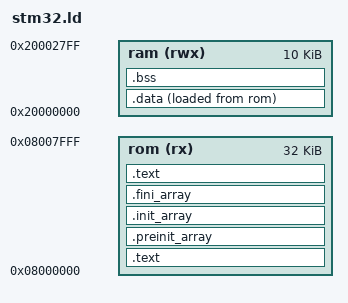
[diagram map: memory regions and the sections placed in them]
/*
 * This file is part of the libopencm3 project.
 *
 * Copyright (C) 2012 Karl Palsson <karlp@tweak.net.au>
 *
 * This library is free software: you can redistribute it and/or modify
 * it under the terms of the GNU Lesser General Public License as published by
 * the Free Software Foundation, either version 3 of the License, or
 * (at your option) any later version.
 *
 * This library is distributed in the hope that it will be useful,
 * but WITHOUT ANY WARRANTY; without even the implied warranty of
 * MERCHANTABILITY or FITNESS FOR A PARTICULAR PURPOSE.  See the
 * GNU Lesser General Public License for more details.
 *
 * You should have received a copy of the GNU Lesser General Public License
 * along with this library.  If not, see <http://www.gnu.org/licenses/>.
 */

/* Linker script for STM32F100x6, 32K flash, 4K RAM. */

/* Define memory regions. */
MEMORY
{
	rom (rx) : ORIGIN = 0x08000000, LENGTH = 32K
	ram (rwx) : ORIGIN = 0x20000000, LENGTH = 10K
}

/* Include the common ld script. */

/*
 * This file is part of the libopencm3 project.
 *
 * Copyright (C) 2009 Uwe Hermann <uwe@hermann-uwe.de>
 *
 * This library is free software: you can redistribute it and/or modify
 * it under the terms of the GNU Lesser General Public License as published by
 * the Free Software Foundation, either version 3 of the License, or
 * (at your option) any later version.
 *
 * This library is distributed in the hope that it will be useful,
 * but WITHOUT ANY WARRANTY; without even the implied warranty of
 * MERCHANTABILITY or FITNESS FOR A PARTICULAR PURPOSE.  See the
 * GNU Lesser General Public License for more details.
 *
 * You should have received a copy of the GNU Lesser General Public License
 * along with this library.  If not, see <http://www.gnu.org/licenses/>.
 */

/* Generic linker script for STM32 targets using libopencm3. */

/* Memory regions must be defined in the ld script which includes this one. */

/* Enforce emmition of the vector table. */
EXTERN (vector_table)

/* Force re-entry symbol to be kept */

EXTERN (reenter_bootloader_addr)

/* Define the entry point of the output file. */
ENTRY(reset_handler)

/* Define sections. */
SECTIONS
{
	.text : {
		*(.vectors)	/* Vector table */
		*(.text*)	/* Program code */
		*(.bootloader*)	/* Sect containing force_bootloader */
		. = ALIGN(4);
		*(.rodata*)	/* Read-only data */
	} >rom

	/* C++ Static constructors/destructors, also used for __attribute__
	 * ((constructor)) and the likes */
	.preinit_array : {
		. = ALIGN(4);
		__preinit_array_start = .;
		KEEP (*(.preinit_array))
		__preinit_array_end = .;
	} >rom
	.init_array : {
		. = ALIGN(4);
		__init_array_start = .;
		KEEP (*(SORT(.init_array.*)))
		KEEP (*(.init_array))
		__init_array_end = .;
	} >rom
	.fini_array : {
		. = ALIGN(4);
		__fini_array_start = .;
		KEEP (*(.fini_array))
		KEEP (*(SORT(.fini_array.*)))
		__fini_array_end = .;
	} >rom

	. = ALIGN(4);
	_etext = .;

	.data : {
		_data = .;
		*(.data*)	/* Read-write initialized data */
		. = ALIGN(4);
		_edata = .;
	} >ram AT >rom
	_data_loadaddr = LOADADDR(.data);

	.bss : {
		*(.bss*)	/* Read-write zero initialized data */
		*(COMMON)
		. = ALIGN(4);
		_ebss = .;
	} >ram

	/*
	 * The .eh_frame section appears to be used for C++ exception handling.
	 * You may need to fix this if you're using C++.
	 */
	/DISCARD/ : { *(.eh_frame) }

	/* Finally, dump a re-enter bootloader pointer at the end of mem */
	.text : {
		. = 0x1FE0;
		*(.sernum*)
		. = 0x1FFC;
		*(.reentry*)
	} >rom

	end = .;
}

PROVIDE(_stack = ORIGIN(ram) + LENGTH(ram));

